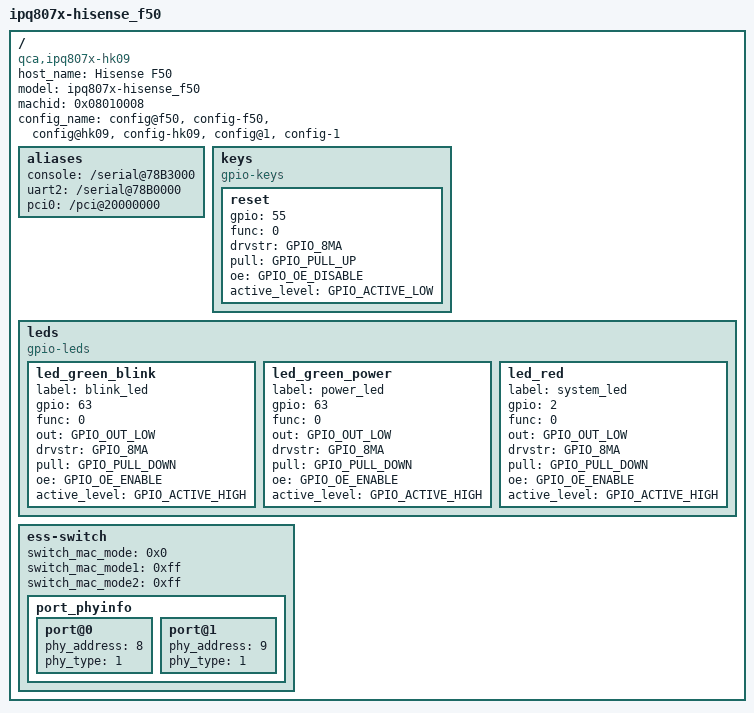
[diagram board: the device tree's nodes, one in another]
/*
 * HISENSE F50 (IPQ8072 / IPQ807x AP-HK09)
 *
 * 注意: 这是 QSDK U-Boot 专用 DTS, 语法与 Linux/OpenWrt DTS 不同.
 *       pinctrl / regulator / wifi / pcie / usb / 分区表 这里都不需要写,
 *       分区表运行时由 U-Boot 从 MIBIB 读取.
 *
 * 数据来源:
 *   1. 原厂 U-Boot 传给内核的活动设备树 (device_tree.dts)
 *      - machid = 0x8000108
 *      - compatible = "qcom,ipq807x-hk09"
 *      - reset 键 = tlmm 55 (低有效)
 *      - led_5g = tlmm 61 / led_2g = tlmm 62 / led_signal_r = tlmm 2 / led_signal_g = tlmm 63
 *      - dp1(phy 8) / dp2(phy 9) / dp5(phy 4, QGMAC) 
 *   2. OpenWrt 适配用的 Linux DTS (ipq8072-f50.dts)
 */

/dts-v1/;
#include "ipq807x-soc.dtsi"
#include <dt-bindings/gpio/gpio.h>
#include <dt-bindings/qcom/gpio-ipq807x.h>

/ {
	host_name = "Hisense F50";
	model = "ipq807x-hisense_f50";
	compatible = "qca,ipq807x-hk09", "qca,ipq807x";
	machid = <0x08010008>;
	config_name = "config@f50", "config-f50", "config@hk09", "config-hk09", "config@1", "config-1";

	aliases {
		console = "/serial@78B3000";
		uart2 = "/serial@78B0000";
		pci0 = "/pci@20000000";
	};

	keys {
		compatible = "gpio-keys";

		/* 复位键: 按住 3 秒进 Web failsafe (gpio 55 低有效) */
		reset {
			gpio = <55>;
			func = <0>;
			drvstr = <GPIO_8MA>;
			pull = <GPIO_PULL_UP>;
			oe = <GPIO_OE_DISABLE>;
			active_level = <GPIO_ACTIVE_LOW>;
		};
	};

	leds {
		compatible = "gpio-leds";

		/*
		 * U-Boot 只认 3 个 label: blink_led / power_led / system_led
		 *   power_led  : 按键倒计时闪烁(闪 3 次)、刷机失败时常亮
		 *   blink_led  : httpd 运行中/上传中常亮
		 *   system_led : 刷机成功时常亮
		 * 这里把 power_led 与 blink_led 放在同一颗绿灯(63)上,
		 * 效果就是 README 里描述的"闪 3 次后常亮"。
		 */
		led_green_blink {
			label = "blink_led";
			gpio = <63>;
			func = <0>;
			out = <GPIO_OUT_LOW>;
			drvstr = <GPIO_8MA>;
			pull = <GPIO_PULL_DOWN>;
			oe = <GPIO_OE_ENABLE>;
			active_level = <GPIO_ACTIVE_HIGH>;
		};

		led_green_power {
			label = "power_led";
			gpio = <63>;
			func = <0>;
			out = <GPIO_OUT_LOW>;
			drvstr = <GPIO_8MA>;
			pull = <GPIO_PULL_DOWN>;
			oe = <GPIO_OE_ENABLE>;
			active_level = <GPIO_ACTIVE_HIGH>;
		};

		/* 信号红灯(2): 刷机成功常亮 */
		led_red {
			label = "system_led";
			gpio = <2>;
			func = <0>;
			out = <GPIO_OUT_LOW>;
			drvstr = <GPIO_8MA>;
			pull = <GPIO_PULL_DOWN>;
			oe = <GPIO_OE_ENABLE>;
			active_level = <GPIO_ACTIVE_HIGH>;
		};
	};

	ess-switch {
		/* UNIPHY0 = PSGMII, 接 QCA8075 (lan1=phy8, lan2=phy9) */
		switch_mac_mode = <0x0>;
		switch_mac_mode1 = <0xff>;
		switch_mac_mode2 = <0xff>;

		port_phyinfo {
			port@0 {
				phy_address = <8>;
				phy_type = <1>;		/* MALIBU_PHY_TYPE = QCA8075 */
			};
			port@1 {
				phy_address = <9>;
				phy_type = <1>;
			};

			/*
			 * WAN 口 (QCA8081 @ mdio 4, 走 QGMAC) 默认不启用。
			 * U-Boot 只需一个能通的口即可进 Web 刷机, 两个 LAN 口已够用。
			 * 若确实需要 WAN 口在 U-Boot 下也能 link, 取消下面注释并把
			 * switch_mac_mode1 改成 <0x1> (SGMII) 或 <0x6> (SGMII_PLUS) 试:
			 *
			 * port@5 {
			 *	phy_address = <4>;
			 *	phy_type = <2>;
			 * };
			 */
		};

		/* 若启用 WAN 口, 同时打开下面两行 (QCA8081 复位 = tlmm 44) */
		/* napa_gpio = <44>; */
		/* napa_gpio_cnt = <1>; */
	};
};
